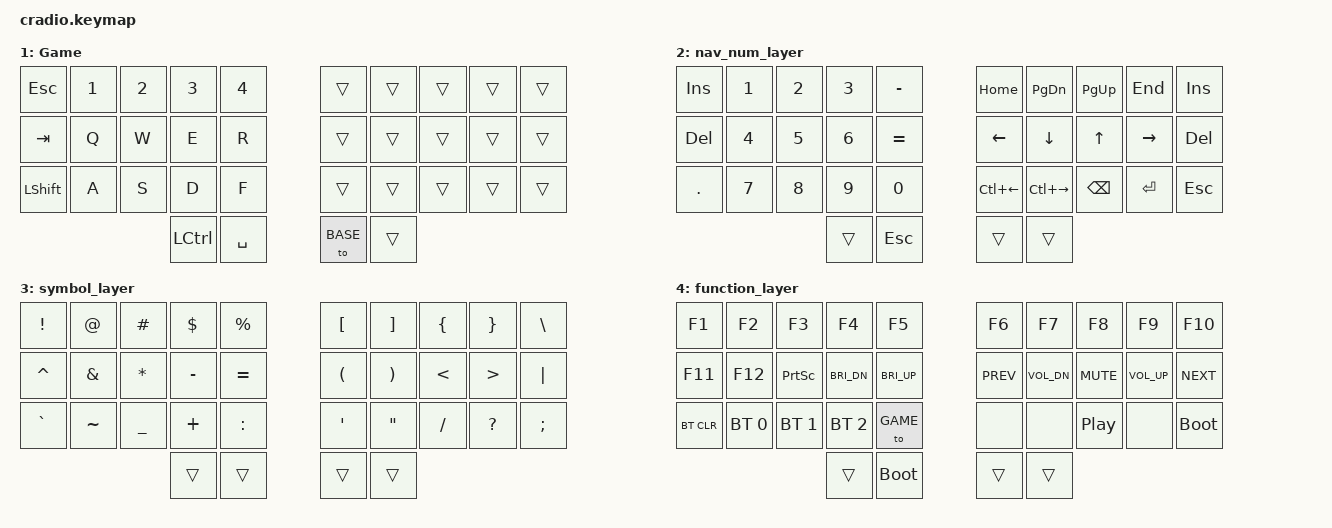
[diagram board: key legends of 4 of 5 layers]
// Copyright (c) 2022 The ZMK Contributors
// SPDX-License-Identifier: MIT

#include <behaviors.dtsi>
#include <dt-bindings/zmk/keys.h>
#include <dt-bindings/zmk/bt.h>

// Home row mods macro
#define HRML(k1,k2,k3,k4) &ht LSHFT k1  &ht LALT k2  &ht LCTRL k3  &ht LGUI k4
#define HRMR(k1,k2,k3,k4) &ht RGUI k1  &ht RCTRL k2  &ht RALT k3  &ht RSHFT k4
#define BASE 0
#define GAME 1
#define NAV_NUM 2
#define SYM 3
#define FUNC 4

/ {
    behaviors {
        ht: hold_tap {
            compatible = "zmk,behavior-hold-tap";
            #binding-cells = <2>;
            flavor = "tap-preferred";
            tapping-term-ms = <220>;
            quick-tap-ms = <150>;
            require-prior-idle-ms = <100>;
            bindings = <&kp>, <&kp>;
        };
    };

    conditional_layers {
        compatible = "zmk,conditional-layers";
        tri_layer {
            if-layers = <NAV_NUM SYM>;
            then-layer = <FUNC>;
        };
    };

    keymap {
        compatible = "zmk,keymap";
        Base_Layer {
            bindings = <
        //╭──────────┬──────────┬──────────┬──────────┬──────────╮   ╭──────────┬──────────┬──────────┬──────────┬──────────╮
        //│  Q       │  W       │  F       │  P       │  B       │   │  J       │  L       │  U       │  Y       │  ;       │
            &kp Q      &kp W      &kp F      &kp P      &kp B          &kp J      &kp L      &kp U      &kp Y      &kp SEMI
        //├──────────┼──────────┼──────────┼──────────┼──────────┤   ├──────────┼──────────┼──────────┼──────────┼──────────┤
        //│  A       │  R       │  S       │  T       │  G       │   │  M       │  N       │  E       │  I       │ O        │
            HRML(A,        R,         S,         T)     &kp G          &kp M      HRMR(N,        E,         I,        O)
        //├──────────┼──────────┼──────────┼──────────┼──────────┤   ├──────────┼──────────┼──────────┼──────────┼──────────┤
        //│  Z       │  X       │  C       │  D       │  V       │   │  K       │  H       │ , <      │ . >      │ /        │
            &kp Z      &kp X      &kp C      &kp D      &kp V          &kp K      &kp H      &kp COMMA  &kp DOT    &kp FSLH
        //╰──────────┴──────────┴──────────┼──────────┼──────────┤   ├──────────┼──────────┼──────────┴──────────┴──────────╯
                                            &lt SYM TAB   &kp ENTER   &kp SPACE  &lt NAV_NUM BSPC
        //                                 ╰──────────┴──────────╯   ╰──────────┴──────────╯
            >;
        };
        
        game_layer {
            display-name = "Game";

            bindings = <

            &kp ESC     &kp N1      &kp N2      &kp N3      &kp N4      &trans &trans &trans &trans &trans

            &kp TAB     &kp Q       &kp W       &kp E       &kp R       &trans &trans &trans &trans &trans
            
            &kp LSHIFT  &kp A       &kp S       &kp D       &kp F       &trans &trans &trans &trans &trans

                                             &kp LCTRL   &kp SPACE      &to BASE &trans

            >;
        };
        // NAV_NUM
        nav_num_layer {
            bindings = <
        //╭──────────┬──────────┬──────────┬──────────┬──────────╮   ╭──────────┬──────────┬──────────┬──────────┬──────────╮
        //│ INSERT   │  1       │  2       │  3       │ -        │   │ HOME     │ PAGE DN  │ PAGE UP  │ END      │  Ins     │
            &kp INS    &kp N1     &kp N2     &kp N3     &kp MINUS     &kp HOME   &kp PG_DN  &kp PG_UP  &kp END    &kp INS
        //├──────────┼──────────┼──────────┼──────────┼──────────┤   ├──────────┼──────────┼──────────┼──────────┼──────────┤
        //│ DELETE   │  4       │  5       │  6       │ =        │   │ LEFT     │ DOWN     │ UP       │ RIGHT    │  Del     │
            &kp DEL    &kp N4     &kp N5     &kp N6     &kp EQUAL     &kp LEFT   &kp DOWN   &kp UP   &kp RIGHT   &kp DEL 
        //├──────────┼──────────┼──────────┼──────────┼──────────┤   ├──────────┼──────────┼──────────┼──────────┼──────────┤
        //│ .        │  7       │  8       │  9       │ 0        │   │LCTRL L   │LCTRL R   │ BSPC     │ENTER     │ESC       │
           &kp DOT     &kp N7     &kp N8     &kp N9     &kp N0      &kp LC(LEFT) &kp LC(RIGHT) &kp BSPC &kp ENTER &kp ESC
        //╰──────────┴──────────┴──────────┼──────────┼──────────┤   ├──────────┼──────────┼──────────┴──────────┴──────────╯
                                             &trans     &kp ESC        &trans     &trans
        //                                 ╰──────────┴──────────╯   ╰──────────┴──────────╯
            >;
        };

        // SYM
        symbol_layer {
            bindings = <
        //╭──────────┬──────────┬──────────┬──────────┬──────────╮   ╭──────────┬──────────┬──────────┬──────────┬──────────╮
        //│  !       │ @        │  #       │  $       │ %        │   │  [       │  ]       │  {       │  }       │  \       │
            &kp EXCL  &kp AT     &kp HASH   &kp DLLR   &kp PRCNT      &kp LBKT   &kp RBKT   &kp LBRC   &kp RBRC   &kp BSLH
        //├──────────┼──────────┼──────────┼──────────┼──────────┤   ├──────────┼──────────┼──────────┼──────────┼──────────┤
        //│  ^       │  &       │  *       │  -       │  =       │   │  (       │  )       │  <       │  >       │  |       │
            &kp CARET &kp AMPS   &kp ASTRK  &kp MINUS  &kp EQUAL      &kp LPAR   &kp RPAR   &kp LT     &kp GT     &kp PIPE
        //├──────────┼──────────┼──────────┼──────────┼──────────┤   ├──────────┼──────────┼──────────┼──────────┼──────────┤
        //│  `       │  ~       │  _       │  +       │  :       │   │  '       │  "       │  /       │  ?       │  ;       │
            &kp GRAVE &kp TILDE  &kp UNDER  &kp PLUS   &kp COLON      &kp SQT    &kp DQT    &kp FSLH   &kp QMARK  &kp SEMI
        //╰──────────┴──────────┴──────────┼──────────┼──────────┤   ├──────────┼──────────┼──────────┴──────────┴──────────╯
                                             &trans     &trans         &trans     &trans
        //                                 ╰──────────┴──────────╯   ╰──────────┴──────────╯
            >;
        };

        // FUNC
        function_layer {
            bindings = <
        //╭──────────┬──────────┬──────────┬──────────┬──────────╮   ╭──────────┬──────────┬──────────┬──────────┬──────────╮
        //│ F1       │ F2       │ F3       │ F4       │ F5       │   │  F6      │  F7      │  F8      │  F9      │ F10      │
           &kp F1     &kp F2     &kp F3     &kp F4     &kp F5          &kp F6     &kp F7     &kp F8     &kp F9    &kp F10
        //├──────────┼──────────┼──────────┼──────────┼──────────┤   ├──────────┼──────────┼──────────┼──────────┼──────────┤
        //│ F11      │ F12      │PrntScreen│Brightness Up/Down   │   │ Prev     │ Vol-     │ MUTE     │ Vol+     │ Next     │
           &kp F11    &kp F12    &kp PSCRN &kp C_BRI_DN&kp C_BRI_UP   &kp C_PREV&kp C_VOL_DN&kp C_MUTE&kp C_VOL_UP &kp C_NEXT
        //├──────────┼──────────┼──────────┼──────────┼──────────┤   ├──────────┼──────────┼──────────┼──────────┼──────────┤
        //│ BTClr    │ BT0      │ BT1      │ BT2      │ GAME     │   │          │          │  Play    │          │ BTLoader │
           &bt BT_CLR&bt BT_SEL 0&bt BT_SEL 1&bt BT_SEL 2&to GAME     &none      &none      &kp C_PP    &none    &bootloader
        //╰──────────┴──────────┴──────────┼──────────┼──────────┤   ├──────────┼──────────┼──────────┴──────────┴──────────╯
                                             &trans     &bootloader   &trans     &trans
        //                                 ╰──────────┴──────────╯   ╰──────────┴──────────╯
            >;
        };
    };
};
